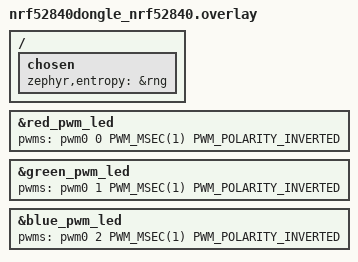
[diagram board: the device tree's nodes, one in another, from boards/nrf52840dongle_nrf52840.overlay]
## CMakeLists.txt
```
#
# Copyright (c) 2018 Nordic Semiconductor
#
# SPDX-License-Identifier: LicenseRef-Nordic-5-Clause
#
cmake_minimum_required(VERSION 3.20.0)

find_package(Zephyr REQUIRED HINTS $ENV{ZEPHYR_BASE})
project(NONE)

FILE(GLOB_RECURSE app_sources src/*.c)
# NORDIC SDK APP START
target_sources(app PRIVATE ${app_sources})
# NORDIC SDK APP END

target_include_directories(app PRIVATE src)

# Force recompile for updated build timestamp
add_custom_target(touch_util_h ALL
    COMMAND ${CMAKE_COMMAND} -E touch ${CMAKE_SOURCE_DIR}/src/build_defines.h
)

target_include_directories(app PRIVATE ${CMAKE_CURRENT_SOURCE_DIR}/../shared)
include(${CMAKE_CURRENT_SOURCE_DIR}/../shared/tdma_hw.cmake)
```

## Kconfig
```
#
# Copyright (c) 2020 Nordic Semiconductor
#
# SPDX-License-Identifier: LicenseRef-Nordic-5-Clause
#

choice
	prompt "Status LED color mapping"
    default LED_TRI_COLOR

config LED_RGB_COLOR
    bool "Use RGB color mapping"
    help
        Use RGB or RG color mapping for LED status if available.

config LED_TRI_COLOR
    bool "Use default color mapping"
    help
        Use the default color mapping for LED status.

endchoice

menu "Status LED default status color"
    depends on LED_RGB_COLOR

config LED_DEFAULT_COLOR_R
    int "Red value"
    range 0 10000
    default 4000
    depends on LED_RGB_COLOR
    help
        Red color for default status.
        Valid range is 0 to 10000.

config LED_DEFAULT_COLOR_G
    int "Green value"
    range 0 10000
    default 6000
    depends on LED_RGB_COLOR
    help
        Green color for default status.
        Valid range is 0 to 10000.

config LED_DEFAULT_COLOR_B
    int "Blue value"
    range 0 10000
    default 0
    depends on LED_RGB_COLOR
    help
        Blue color for default status.
        Valid range is 0 to 10000.

endmenu

config PACKET_LOG
    bool "Link diagnostics and packet log"
    default y
    help
        "diag on" on the console logs radio link diagnostics every interval: frames received and
        lost per tracker (from the frame sequence numbers), repeats, longest silence, RSSI, the
        radio's good/bad CRC counts and the channel's noise floor. Always logged: packets dropped
        by the receiver (unknown id, bad checksum, out of sequence) and trackers gone silent.

config PACKET_LOG_INTERVAL_MS
    int "Log interval (ms)"
    depends on PACKET_LOG
    range 100 60000
    default 1000

config PACKET_LOG_ORIENTATION
    bool "Log each tracker's orientation and packet rate every interval"
    depends on PACKET_LOG
    help
        "Tracker 2 (3CA1B2C4D5E6): orientation X 12.3 Y -4.5 Z 170.2 deg, 98 pkt/s, RSSI ..."
        while "diag" is off.

# "diag on" logs a block of lines every interval; the default 1 KB drops some of them.
config LOG_BUFFER_SIZE
    default 4096 if PACKET_LOG && !SOC_NRF52820

config RECEIVER_BLE
    bool "BLE receiver mode"
    # The Dongle's overlay picks the RNG for entropy (the SoC default, CryptoCell, needs
    # nrf_security); other nRF52840 boards need the same before they can enable it
    default y if BOARD_NRF52840DONGLE
    select BT
    select BT_CENTRAL
    select BT_GATT_CLIENT
    select BT_GATT_DM
    select ESB_DYNAMIC_INTERRUPTS
    select MPSL_DYNAMIC_INTERRUPTS
    help
        Builds a BLE central in beside ESB, for trackers in BLE mode (src/connection/ble.c). The
        receiver_ble setting (console: ble on|off) picks one at boot: the radio runs either ESB
        or BLE, never both; the USB HID output is the same. Changing it reboots the receiver.
        As the tracker (TRACKER_BLE): MPSL keeps its default clock control in both modes and
        stays idle in ESB mode, where ESB takes the radio interrupt over.

if RECEIVER_BLE

config RECEIVER_BLE_MAX_TRACKERS
    int "Trackers connected at once in BLE mode"
    range 1 16
    default 8
    help
        Sets the BLE connections and the connection interval (src/connection/ble.c): each tracker
        gets 1.5 ms of it on 2M (two notification exchanges; 1.9 ms on 1M, RECEIVER_BLE_PHY_1M),
        plus 0.5 ms spare, in 1.25 ms steps: 8 trackers 12.5 ms (up to 160 packets/s each,
        tested), 10 trackers 16.25 ms (~123/s), 12 trackers 18.75 ms (~107/s). The interval is
        fixed for any count connected.

config BT_MAX_CONN
    default RECEIVER_BLE_MAX_TRACKERS

# Each connection 1500 us in the 12.5 ms interval (ble.c, eight trackers): two
# notification exchanges (the controller budgets 27-byte packets both ways, ~0.6 ms each on 2M,
# so 1200 us fitted one); connection event extension gives more while the others leave time
config BT_CTLR_SDC_MAX_CONN_EVENT_LEN_DEFAULT_OVERRIDE
    default y

config BT_CTLR_SDC_MAX_CONN_EVENT_LEN_DEFAULT
    default 1900 if RECEIVER_BLE_PHY_1M
    default 1500

config RECEIVER_BLE_PHY_1M
    bool "BLE on the 1M PHY (range) instead of 2M (rate)"
    help
        The 1M PHY hears about 3 dB weaker signals than 2M (about -95 against -92 dBm), for
        trackers your body blocks; a packet takes twice the air time. The controller's 2M support
        goes, so every link stays on 1M whatever the tracker asks; each tracker gets 1.9 ms of the
        interval (two exchanges budgeted for 27-byte packets both ways, ~0.9 ms each on 1M) and
        the interval follows (ble.c): 8 trackers 16.25 ms (~123 packets/s each), 10 trackers
        20 ms (~100/s).

config BT_CTLR_PHY_2M
    default n if RECEIVER_BLE_PHY_1M

choice BT_AUTO_PHY_CENTRAL
    default BT_AUTO_PHY_CENTRAL_1M if RECEIVER_BLE_PHY_1M
endchoice

choice BT_CTLR_TX_PWR
    default BT_CTLR_TX_PWR_PLUS_8
endchoice

# Each link's PHY in the console's ble status
config BT_USER_PHY_UPDATE
    default y

# HCI Read RSSI, for the RSSI in the HID packets (off by default in the SoftDevice Controller)
config BT_CTLR_CONN_RSSI
    default y

# the BLE host runs parts on the system workqueue (upstream default 1 KB)
config SYSTEM_WORKQUEUE_STACK_SIZE
    default 2048

endif

# LF clock: synthesized from the HF crystal as upstream (no 32 kHz crystal on the Dongle), but
# BLE needs a calibrated RC oscillator under MPSL (500 ppm)
choice CLOCK_CONTROL_NRF_SOURCE
    default CLOCK_CONTROL_NRF_K32SRC_RC if RECEIVER_BLE
    default CLOCK_CONTROL_NRF_K32SRC_SYNTH
endchoice

source "Kconfig.zephyr"
```

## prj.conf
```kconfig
#CONFIG_NCS_SAMPLES_DEFAULTS
CONFIG_ASSERT=y
CONFIG_ASSERT_NO_COND_INFO=y
CONFIG_ASSERT_NO_MSG_INFO=y
CONFIG_RESET_ON_FATAL_ERROR=y

CONFIG_NCS_APPLICATION_BOOT_BANNER_STRING="SlimeVR-Tracker-nRF-Receiver"
#CONFIG_NCS_BOOT_BANNER=n
CONFIG_BOOT_BANNER=n

CONFIG_ESB=y
CONFIG_NEWLIB_LIBC=y
CONFIG_CBPRINTF_FP_SUPPORT=y

CONFIG_FPU=y

CONFIG_USB_DEVICE_STACK=y
CONFIG_USB_DEVICE_HID=y
CONFIG_USB_DEVICE_VID=0x1209
CONFIG_USB_DEVICE_PID=0x7690
CONFIG_USB_HID_BOOT_PROTOCOL=y
CONFIG_USB_DEVICE_INITIALIZE_AT_BOOT=n
CONFIG_USB_CDC_ACM=y
CONFIG_UART_INTERRUPT_DRIVEN=y
#CONFIG_USB_WORKQUEUE_STACK_SIZE=512

CONFIG_SERIAL=y
CONFIG_CONSOLE=y
CONFIG_UART_CONSOLE=y
CONFIG_UART_LINE_CTRL=y

CONFIG_USE_SEGGER_RTT=y
CONFIG_LOG=y
#CONFIG_PRINTK=y
CONFIG_LOG_MODE_DEFERRED=y
CONFIG_LOG_SPEED=y
CONFIG_LOG_BACKEND_RTT=y
CONFIG_USB_DRIVER_LOG_LEVEL_WRN=y
CONFIG_USB_DEVICE_LOG_LEVEL_WRN=y
CONFIG_USB_CDC_ACM_LOG_LEVEL_OFF=y
CONFIG_LOG_PROCESS_THREAD_SLEEP_MS=100
CONFIG_LOG_PROCESS_THREAD_STACK_SIZE=1024
CONFIG_LOG_PROCESS_THREAD_STARTUP_DELAY_MS=0

CONFIG_LOG_BACKEND_UART=y
CONFIG_LOG_MODE_DEFERRED=y

CONFIG_CONSOLE_SUBSYS=y
CONFIG_CONSOLE_GETLINE=y

CONFIG_NVS_LOG_LEVEL_WRN=y
CONFIG_USB_HID_LOG_LEVEL_WRN=y

CONFIG_USB_DEVICE_SOF=y
CONFIG_USB_HID_REPORTS=256

CONFIG_USB_HID_POLL_INTERVAL_MS=1
CONFIG_HID_INTERRUPT_EP_MPS=64
CONFIG_ENABLE_HID_INT_OUT_EP=y

CONFIG_GPIO=y
CONFIG_PWM=y

CONFIG_NVS=y

CONFIG_FLASH=y
CONFIG_FLASH_PAGE_LAYOUT=y
CONFIG_FLASH_MAP=y

CONFIG_SETTINGS=y
CONFIG_SETTINGS_NVS=y
CONFIG_SETTINGS_RUNTIME=y
CONFIG_SETTINGS_NONE=y

CONFIG_MPU_ALLOW_FLASH_WRITE=y

CONFIG_NVS_LOOKUP_CACHE=y

CONFIG_ESB_TX_FIFO_SIZE=1
# deprecated?
#CONFIG_NRFX_TIMER1=y

#speed up boot? (use internal rc oscillator)
#CONFIG_CLOCK_CONTROL_NRF_K32SRC_RC=y
#speed up boot? (synthesize lf clock)
# SYNTH, unless the BLE mode is built in (Kconfig, RECEIVER_BLE: calibrated RC)
#CONFIG_CLOCK_CONTROL_NRF_K32SRC_SYNTH=y

# dont need it
CONFIG_CRYPTO=n

CONFIG_THREAD_NAME=y
#CONFIG_SYSTEM_WORKQUEUE_STACK_SIZE=256
CONFIG_MAIN_STACK_SIZE=512

#CONFIG_HEAP_MEM_POOL_SIZE=2048
CONFIG_ISR_STACK_SIZE=1024
```

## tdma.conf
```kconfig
# Experimental; requires TDMA firmware on every tracker for collision isolation.
CONFIG_RADIO_TDMA=y
CONFIG_STACK_USAGE=y
```

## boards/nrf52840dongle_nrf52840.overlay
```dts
&red_pwm_led {
	pwms = <&pwm0 0 PWM_MSEC(1) PWM_POLARITY_INVERTED>;
};
&green_pwm_led {
	pwms = <&pwm0 1 PWM_MSEC(1) PWM_POLARITY_INVERTED>;
};
&blue_pwm_led {
	pwms = <&pwm0 2 PWM_MSEC(1) PWM_POLARITY_INVERTED>;
};

/* BLE mode (CONFIG_RECEIVER_BLE): random numbers from the RNG peripheral. The SoC default is
 * CryptoCell, whose driver needs nrf_security. */
/ {
	chosen {
		zephyr,entropy = &rng;
	};
};
```

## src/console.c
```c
/*
	SlimeVR Code is placed under the MIT license
	Copyright (c) 2025 SlimeVR Contributors

	Permission is hereby granted, free of charge, to any person obtaining a copy
	of this software and associated documentation files (the "Software"), to deal
	in the Software without restriction, including without limitation the rights
	to use, copy, modify, merge, publish, distribute, sublicense, and/or sell
	copies of the Software, and to permit persons to whom the Software is
	furnished to do so, subject to the following conditions:

	The above copyright notice and this permission notice shall be included in
	all copies or substantial portions of the Software.

	THE SOFTWARE IS PROVIDED "AS IS", WITHOUT WARRANTY OF ANY KIND, EXPRESS OR
	IMPLIED, INCLUDING BUT NOT LIMITED TO THE WARRANTIES OF MERCHANTABILITY,
	FITNESS FOR A PARTICULAR PURPOSE AND NONINFRINGEMENT. IN NO EVENT SHALL THE
	AUTHORS OR COPYRIGHT HOLDERS BE LIABLE FOR ANY CLAIM, DAMAGES OR OTHER
	LIABILITY, WHETHER IN AN ACTION OF CONTRACT, TORT OR OTHERWISE, ARISING FROM,
	OUT OF OR IN CONNECTION WITH THE SOFTWARE OR THE USE OR OTHER DEALINGS IN
	THE SOFTWARE.
*/
#include "connection/ble.h"
#include "globals.h"
#include "system/system.h"
#include "build_defines.h"
#include "parse_args.h"
#include "packet_log.h"
#include "ota.h"
#include "remote_config.h"

#define USB DT_NODELABEL(usbd)
#if DT_NODE_HAS_STATUS(USB, okay)

#include <zephyr/drivers/gpio.h>
#include <zephyr/console/console.h>
#include <stdlib.h>
#include <zephyr/sys/reboot.h>
#include <zephyr/logging/log_ctrl.h>
#include "connection/esb.h"

#include <ctype.h>

#define DFU_DBL_RESET_MEM 0x20007F7C
#define DFU_DBL_RESET_APP 0x4ee5677e

uint32_t* dbl_reset_mem = ((uint32_t*) DFU_DBL_RESET_MEM);

LOG_MODULE_REGISTER(console, LOG_LEVEL_INF);

static void console_thread(void);
K_THREAD_DEFINE(console_thread_id, 1024, console_thread, NULL, NULL, NULL, 6, 0, 0);

#define DFU_EXISTS CONFIG_BUILD_OUTPUT_UF2 || CONFIG_BOARD_HAS_NRF5_BOOTLOADER
#define ADAFRUIT_BOOTLOADER CONFIG_BUILD_OUTPUT_UF2
#define NRF5_BOOTLOADER CONFIG_BOARD_HAS_NRF5_BOOTLOADER

#if NRF5_BOOTLOADER
static const struct device *gpio_dev = DEVICE_DT_GET(DT_NODELABEL(gpio0));
#endif

static const char *meows[] = {
	"Mew",
	"Meww",
	"Meow",
	"Meow meow",
	"Mrrrp",
	"Mrrf",
	"Mreow",
	"Mrrrow",
	"Mrrr",
	"Purr",
	"mew",
	"meww",
	"meow",
	"meow meow",
	"mrrrp",
	"mrrf",
	"mreow",
	"mrrrow",
	"mrrr",
	"purr",
};

static const char *meow_punctuations[] = {
	".",
	"?",
	"!",
	"-",
	"~",
	""
};

static const char *meow_suffixes[] = {
	" :3",
	" :3c",
	" ;3",
	" ;3c",
	" x3",
	" x3c",
	" X3",
	" X3c",
	" >:3",
	" >:3c",
	" >;3",
	" >;3c",
	""
};

static void skip_dfu(void)
{
#if DFU_EXISTS // Using Adafruit bootloader
	(*dbl_reset_mem) = DFU_DBL_RESET_APP; // Skip DFU
	ram_range_retain(dbl_reset_mem, sizeof(dbl_reset_mem), true);
#endif
}

static void print_info(void)
{
	printk(CONFIG_USB_DEVICE_MANUFACTURER " " CONFIG_USB_DEVICE_PRODUCT "\n");
	printk(FW_STRING);

	printk("\nBoard: " CONFIG_BOARD "\n");
	printk("SOC: " CONFIG_SOC "\n");
	printk("Target: " CONFIG_BOARD_TARGET "\n");

	printk("\nDevice address: %012llX\n", *(uint64_t *)NRF_FICR->DEVICEADDR & 0xFFFFFFFFFFFF);
}

static void print_uptime(void)
{
	int64_t uptime = k_ticks_to_us_floor64(k_uptime_ticks());

	uint32_t days = uptime / 86400000000;
	uptime %= 86400000000;
	uint8_t hours = uptime / 3600000000;
	uptime %= 3600000000;
	uint8_t minutes = uptime / 60000000;
	uptime %= 60000000;
	uint8_t seconds = uptime / 1000000;
	uptime %= 1000000;
	uint16_t milliseconds = uptime / 1000;
	uint16_t microseconds = uptime %= 1000;

	printk("Uptime: %u.%02u:%02u:%02u.%03u,%03u\n", days, hours, minutes, seconds, milliseconds, microseconds);
}

static void print_meow(void)
{
	int64_t ticks = k_uptime_ticks();

	ticks %= ARRAY_SIZE(meows) * ARRAY_SIZE(meow_punctuations) * ARRAY_SIZE(meow_suffixes); // silly number generator
	uint8_t meow = ticks / (ARRAY_SIZE(meow_punctuations) * ARRAY_SIZE(meow_suffixes));
	ticks %= (ARRAY_SIZE(meow_punctuations) * ARRAY_SIZE(meow_suffixes));
	uint8_t punctuation = ticks / ARRAY_SIZE(meow_suffixes);
	uint8_t suffix = ticks % ARRAY_SIZE(meow_suffixes);

	printk("%s%s%s\n", meows[meow], meow_punctuations[punctuation], meow_suffixes[suffix]);
}

static void print_list(void)
{
	printk("Stored devices:\n");
	for (uint8_t i = 0; i < stored_trackers; i++)
		printk("%012llX%s\n", stored_tracker_addr[i], stored_tracker_addr[i] ? "" : " (free, unpaired)");
}

static inline void strtolower(char *str) {
	for(int i = 0; str[i]; i++) {
		str[i] = tolower(str[i]);
	}
}

static void print_help(void)
{
	printk("\nhelp                         Display this help text\n");

	printk("\ninfo                         Get device information\n");
	printk("uptime                       Get device uptime\n");
	printk("list                         Get paired devices\n");
	printk("reboot                       Soft reset the device\n");
	printk("\nadd <address>                Manually add a device\n");
	printk("remove                       Remove last device\n");
	printk("unpair <id>                  Remove that device; the others keep their ids\n");
	printk("pair                         Enter pairing mode\n");
	printk("exit                         Exit pairing mode\n");
	printk("clear                        Clear stored devices\n");
#if CONFIG_PACKET_LOG
	printk("\ndiag [on|off]                Log radio link diagnostics every second (off at boot)\n");
#endif
	printk("ota [status|stop]            Tracker firmware updates over the radio (tools/ota.py)\n");
	printk("cfg <id> get|set|reset ...   Tracker settings over the radio (tools/remote_config.py)\n");
#if CONFIG_RECEIVER_BLE
	printk("ble [on|off]                 BLE status, or switch to BLE / ESB (reboots)\n");
#endif
#if DFU_EXISTS
	printk("\ndfu                          Enter DFU bootloader\n");
#endif
	printk("\nmeow                         Meow!\n");
}

static void console_thread(void)
{
	console_getline_init();
	while (log_data_pending())
		k_usleep(1);
	k_msleep(100);
	printk("*** " CONFIG_USB_DEVICE_MANUFACTURER " " CONFIG_USB_DEVICE_PRODUCT " ***\n");
	printk(FW_STRING);
	print_help();

	const char command_help[] = "help";

	const char command_info[] = "info";
	const char command_uptime[] = "uptime";
	const char command_list[] = "list";
	const char command_reboot[] = "reboot";
	const char command_add[] = "add";
	const char command_remove[] = "remove";
	const char command_pair[] = "pair";
	const char command_exit[] = "exit";
	const char command_clear[] = "clear";
#if DFU_EXISTS
	const char command_dfu[] = "dfu";
#endif
	const char command_meow[] = "meow";
	const char command_diag[] = "diag";

	while (1) {
		char *line = console_getline();

		char* argv[8] = {NULL}; // command and up to 6 args (the parser rejects a full array; ota begin has 4)
		size_t argc = parse_args(line, argv, ARRAY_SIZE(argv));
		if(argc == 0)
			continue;
		if(argc > 0)
			strtolower(argv[0]); // lower case the command
		if(argc > 1)
			strtolower(argv[1]); // lower case the first argument
		// only care that the first words are matchable

		if (strcmp(argv[0], command_help) == 0)
		{
			print_help();
		}
		else if (strcmp(argv[0], command_info) == 0)
		{
			print_info();
		}
		else if (strcmp(line, command_uptime) == 0)
		{
			print_uptime();
		}
		else if (strcmp(line, command_add) == 0)
		{
			if (argc != 2)
			{
				printk("Invalid number of arguments\n");
				continue;
			}
			uint64_t addr = parse_u64(argv[1], 16);
			uint8_t buf[13];
			snprintk(buf, 13, "%012llx", addr);
			if (addr != 0 && strcmp(buf, argv[1]) == 0)
				esb_add_pair(addr, true);
			else
				printk("Invalid address\n");
		}
		else if (strcmp(line, command_remove) == 0)
		{
			esb_pop_pair();
			ble_disconnect_all(); // ids anew as they reconnect
		}
		else if (strcmp(line, command_list) == 0)
		{
			print_list();
		}
		else if (strcmp(line, command_reboot) == 0)
		{
			skip_dfu();
			sys_reboot(SYS_REBOOT_COLD);
		}
		else if (strcmp(line, command_pair) == 0)
		{
			if (ble_mode())
				ble_set_pairing(true);
			else
				esb_reset_pair();
			printk("Pairing on%s\n", ble_mode() ? " (BLE: new trackers in BLE mode are added when they connect)" : "");
		}
		else if (strcmp(line, command_exit) == 0)
		{
			if (ble_mode())
				ble_set_pairing(false);
			else
				esb_finish_pair();
			printk("Pairing off\n");
		}
		else if (strcmp(argv[0], "unpair") == 0)
		{
			char *end = NULL;
			unsigned long id = argc == 2 ? strtoul(argv[1], &end, 10) : 0;
			if (argc != 2 || !end || *end || id > 255)
				printk("Usage: unpair <id>\n");
			else if (esb_unpair(id))
				printk("Unpair: no device on id %lu\n", id);
			else
			{
				ble_disconnect_id(id);
				printk("Unpaired id %lu\n", id);
			}
		}
		else if (strcmp(line, command_clear) == 0)
		{
			esb_clear();
			ble_disconnect_all(); // ids anew as they reconnect
		}
#if CONFIG_RECEIVER_BLE
		else if (strcmp(argv[0], "ble") == 0)
		{
			if (argc == 2 && (strcmp(argv[1], "on") == 0 || strcmp(argv[1], "off") == 0))
				ble_set_mode(strcmp(argv[1], "on") == 0);
			else if (argc == 1)
				ble_print_status();
			else
				printk("Usage: ble [on|off]\n");
		}
#endif
#if DFU_EXISTS
		else if (strcmp(line, command_dfu) == 0)
		{
#if ADAFRUIT_BOOTLOADER
			NRF_POWER->GPREGRET = 0x57;
			sys_reboot(SYS_REBOOT_COLD);
#endif
#if NRF5_BOOTLOADER
			gpio_pin_configure(gpio_dev, 19, GPIO_OUTPUT | GPIO_OUTPUT_INIT_LOW);
#endif
		}
#endif
		else if (strcmp(line, command_meow) == 0)
		{
			print_meow();
		}
		else if (strcmp(argv[0], "ota") == 0)
		{
			ota_console(argc, argv);
		}
		else if (strcmp(argv[0], "cfg") == 0)
		{
			remote_config_console(argc, argv);
		}
		else if (strcmp(argv[0], command_diag) == 0)
		{
			if (!IS_ENABLED(CONFIG_PACKET_LOG))
				printk("This build has no link diagnostics\n");
			else
			{
				if (argc > 1 && (strcmp(argv[1], "on") == 0 || strcmp(argv[1], "off") == 0))
					packet_log_set_diag(strcmp(argv[1], "on") == 0);
				else if (argc > 1)
					printk("Usage: diag [on|off]\n");
				printk("Link diagnostics %s\n", packet_log_diag() ? "on" : "off");
				if (packet_log_diag())
					printk("Every second:\n"
					       "  diag noise: background RSSI while listening; the median is the noise floor (clean: about -95)\n"
					       "  diag radio: frames the radio received with a good / bad CRC, all trackers\n"
					       "  diag id N: rx frames, lost = sequence numbers that never arrived,\n"
					       "    dup = repeats (tracker missed the ACK), late = older after newer,\n"
					       "    max gap = longest silence, RSSI average (worst),\n"
					       "    |...| = 50 ms slots: # frames, x frames after lost ones, . nothing\n"
					       "  diag gap / outage: a silence that lost frames, or over 1 s\n");
			}
		}
		else
		{
			printk("Unknown command\n");
		}
	}
}

#endif
```

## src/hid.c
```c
/*
	SlimeVR Code is placed under the MIT license
	Copyright (c) 2025 SlimeVR Contributors

	Permission is hereby granted, free of charge, to any person obtaining a copy
	of this software and associated documentation files (the "Software"), to deal
	in the Software without restriction, including without limitation the rights
	to use, copy, modify, merge, publish, distribute, sublicense, and/or sell
	copies of the Software, and to permit persons to whom the Software is
	furnished to do so, subject to the following conditions:

	The above copyright notice and this permission notice shall be included in
	all copies or substantial portions of the Software.

	THE SOFTWARE IS PROVIDED "AS IS", WITHOUT WARRANTY OF ANY KIND, EXPRESS OR
	IMPLIED, INCLUDING BUT NOT LIMITED TO THE WARRANTIES OF MERCHANTABILITY,
	FITNESS FOR A PARTICULAR PURPOSE AND NONINFRINGEMENT. IN NO EVENT SHALL THE
	AUTHORS OR COPYRIGHT HOLDERS BE LIABLE FOR ANY CLAIM, DAMAGES OR OTHER
	LIABILITY, WHETHER IN AN ACTION OF CONTRACT, TORT OR OTHERWISE, ARISING FROM,
	OUT OF OR IN CONNECTION WITH THE SOFTWARE OR THE USE OR OTHER DEALINGS IN
	THE SOFTWARE.
*/
#include "globals.h"
#include "packet_log.h"
#include "ota.h"

#include <zephyr/kernel.h>
#include <zephyr/usb/usb_device.h>
#include <zephyr/usb/class/usb_hid.h>

static struct k_work report_send;
static struct k_work report_read;

static struct tracker_report {
	uint8_t data[16];
} __packed report = {
	.data = {0}
};;

struct tracker_report reports[MAX_TRACKERS];
atomic_t report_write_index = 0;
atomic_t report_read_index = 0;
// read_index == write_index -> empty fifo
// (write_index + 1) % MAX_TRACKERS == read_index -> full fifo

static bool configured;
static const struct device *hdev;
static ATOMIC_DEFINE(hid_ep_in_busy, 1);
static ATOMIC_DEFINE(hid_ep_out_busy, 1);

#define HID_EP_BUSY_FLAG	0
#define REPORT_PERIOD		K_MSEC(1) // streaming reports // TODO: could it be shorter/reduce latency?
#define POLL_PERIOD		K_MSEC(1) // streaming reports // TODO: could it be shorter/reduce latency?
#define HID_EP_REPORT_COUNT 4

struct tracker_report ep_report_buffer[HID_EP_REPORT_COUNT];
uint8_t ep_read_buffer[256]; // TODO: no struct // TODO: is possible to read >64 bytes, e.g. a delayed read?

LOG_MODULE_REGISTER(hid_event, LOG_LEVEL_INF);

static void report_event_handler(struct k_timer *dummy);
static K_TIMER_DEFINE(event_timer, report_event_handler, NULL);

static void report_read_handler(struct k_timer *dummy);
static K_TIMER_DEFINE(read_timer, report_read_handler, NULL);

static const uint8_t hid_report_desc[] = {
	HID_USAGE_PAGE(HID_USAGE_GEN_DESKTOP),
	HID_USAGE(HID_USAGE_GEN_DESKTOP_UNDEFINED),
	HID_COLLECTION(HID_COLLECTION_APPLICATION),
		HID_USAGE(HID_USAGE_GEN_DESKTOP_UNDEFINED),
		HID_REPORT_SIZE(8),
		HID_REPORT_COUNT(64),
		HID_INPUT(0x02),
		HID_USAGE(HID_USAGE_GEN_DESKTOP_UNDEFINED),
		HID_REPORT_SIZE(8),
		HID_REPORT_COUNT(64),
		HID_OUTPUT(0x02),
	HID_END_COLLECTION,
};

uint16_t sent_device_addr = 0;
bool usb_enabled = false;
int64_t last_registration_sent = 0;

//|type    |description
//|TX   255|receiver packet 0, associate id and tracker address
//|TX   254|device list hash, round trip ping
//|TX   253|receiver status (TODO: send number of pairing requests found?)
//|TX   252|device pairing request, id is the id of the pairing request in case of multiple, not final tracker id (TODO: these can timeout if not sent often? can server automatically accept if the address was known?)
//|RX   255|round trip response
//|RX   254|command (TODO: include parameters?)

//|b0      |b1      |b2      |b3      |b4      |b5      |b6      |b7      |b8      |b9      |b10     |b11     |b12     |b13     |b14     |b15     |
//|type    |data                                                                                                                                  |
//|TX   255|id      |device_addr                                          |resv-------------------------------------------------------------------|
//|TX   254|stored  |crc                                |latency          |resv-------------------------------------------------------------------|
//|TX   253|status  |resv-------------------------------------------------|resv-------------------------------------------------------------------|
//|TX   252|id      |device_addr                                          |resv-------------------------------------------------------------------|
//|RX   255|resv----------------------------------------------------------|resv-------------------------------------------------------------------|
//|RX   254|command |resv-------------------------------------------------|resv-------------------------------------------------------------------|

// TODO: implement this

static void packet_device_addr(uint8_t *report, uint16_t id) // associate id and tracker address
{
	report[0] = 255; // receiver packet 0
	report[1] = id;
	memcpy(&report[2], &stored_tracker_addr[id], 6);
	memset(&report[8], 0, 8); // last 8 bytes unused for now
}

static uint32_t dropped_reports = 0;
static uint16_t max_dropped_reports = 0;

// The next paired id after `id`, round robin, skipping ids freed by unpair (address 0); -1: none
static int next_paired(int id)
{
	for (int k = 0; k < stored_trackers; k++)
	{
		id = (id + 1) % stored_trackers;
		if (stored_tracker_addr[id])
			return id;
	}
	return -1;
}

static void send_report(struct k_work *work)
{
	if (!usb_enabled) return;
	if (next_paired(0) < 0) return; // no paired tracker (an empty slot would read as a tracker packet)

	// Get current FIFO status atomically
	size_t write_idx = (size_t)atomic_get(&report_write_index);
	size_t read_idx = (size_t)atomic_get(&report_read_index);

	if (write_idx == read_idx && k_uptime_get() - 100 < last_registration_sent) {
		return; // send registrations only every 100ms
	}

	int ret, wrote;

	last_registration_sent = k_uptime_get();

	if (!atomic_test_and_set_bit(hid_ep_in_busy, HID_EP_BUSY_FLAG)) {
		// Calculate how many reports we have available
		int available_reports = write_idx - read_idx;
		if (available_reports < 0) available_reports += MAX_TRACKERS;
		size_t reports_to_send = (size_t)((available_reports > HID_EP_REPORT_COUNT) ? HID_EP_REPORT_COUNT : available_reports);

		int epind;
		// Copy existing data to buffer
		for (epind = 0; epind < reports_to_send; epind++) {
			ep_report_buffer[epind] = reports[read_idx];
			read_idx++;
			if (read_idx == MAX_TRACKERS) read_idx = 0;
			atomic_set(&report_read_index, read_idx);
		}

		// Pad remaining report slots with device addr
		for (; epind < HID_EP_REPORT_COUNT; epind++) {
			int id = next_paired(sent_device_addr);
			if (id >= 0) {
				sent_device_addr = id;
				packet_device_addr(ep_report_buffer[epind].data, sent_device_addr);
			}
		}

		ret = hid_int_ep_write(hdev, (uint8_t *)ep_report_buffer, sizeof(report) * HID_EP_REPORT_COUNT, &wrote);

		if (ret != 0) {
			/*
			 * Do nothing and wait until host has reset the device
			 * and hid_ep_in_busy is cleared.
			 */
			LOG_ERR("Failed to submit report");
		} else {
			//LOG_DBG("Report submitted");
		}
	} else { // busy with what
		//LOG_DBG("HID IN endpoint busy");
	}
}

#define DROPPED_REPORT_LOG_INTERVAL 5000

static void hid_dropped_reports_logging(void)
{
	while (1) {
		if (dropped_reports) LOG_INF("Dropped reports: %u (max: %u)", dropped_reports, max_dropped_reports);
		dropped_reports = 0;
		max_dropped_reports = 0;
		k_msleep(DROPPED_REPORT_LOG_INTERVAL);
	}
}

K_THREAD_DEFINE(hid_dropped_reports_logging_thread, 256, hid_dropped_reports_logging, NULL, NULL, NULL, 6, 0, 0);

static void read_report(struct k_work *work)
{
	if (!usb_enabled) return;

	int ret, read;

	if (!atomic_test_and_set_bit(hid_ep_out_busy, HID_EP_BUSY_FLAG)) {
		ret = hid_int_ep_read(hdev, (uint8_t *)ep_read_buffer, sizeof(ep_read_buffer), &read);

		if (ret != 0) {
			LOG_ERR("hid_int_ep_read: %d", ret);
		} else if (read > 0 && ep_read_buffer[0] == OTA_HID_DATA) {
			ota_hid_data(ep_read_buffer, read); // a tracker firmware update streamed by the PC
		} else {
			LOG_INF("hid_int_ep_read: %d", read);
			// do something here
			LOG_INF("%016llX%016llX%016llX%016llX%016llX%016llX%016llX%016llX",
				*(uint64_t *)(ep_read_buffer + 56),
				*(uint64_t *)(ep_read_buffer + 48),
				*(uint64_t *)(ep_read_buffer + 40),
				*(uint64_t *)(ep_read_buffer + 32),
				*(uint64_t *)(ep_read_buffer + 24),
				*(uint64_t *)(ep_read_buffer + 16),
				*(uint64_t *)(ep_read_buffer + 8),
				*(uint64_t *)ep_read_buffer
			);
		}
	} else { // busy with what
		//LOG_DBG("HID OUT endpoint busy");
	}
}

static void int_in_ready_cb(const struct device *dev)
{
	ARG_UNUSED(dev);
	if (!atomic_test_and_clear_bit(hid_ep_in_busy, HID_EP_BUSY_FLAG)) {
		LOG_WRN("IN endpoint callback without preceding buffer write");
	}
	// TODO: can probably immediately write report from here
}

static void int_out_ready_cb(const struct device *dev)
{
	ARG_UNUSED(dev);
	if (!atomic_test_and_clear_bit(hid_ep_out_busy, HID_EP_BUSY_FLAG)) {
		LOG_WRN("OUT endpoint callback without preceding buffer write");
	}
	// TODO: can probably immediately read report from here
}

/*
 * On Idle callback is available here as an example even if actual use is
 * very limited. In contrast to report_event_handler(),
 * report value is not incremented here.
 */
static void on_idle_cb(const struct device *dev, uint16_t report_id)
{
	LOG_DBG("On idle callback");
	k_work_submit(&report_send);
}

static void report_event_handler(struct k_timer *dummy)
{
	if (usb_enabled)
		k_work_submit(&report_send);
}

static void report_read_handler(struct k_timer *dummy)
{
	if (usb_enabled)
		k_work_submit(&report_read);
}

static void protocol_cb(const struct device *dev, uint8_t protocol)
{
	LOG_INF("New protocol: %s", protocol == HID_PROTOCOL_BOOT ?
		"boot" : "report");
}

static const struct hid_ops ops = {
	.int_in_ready = int_in_ready_cb,
	.int_out_ready = int_out_ready_cb,
	.on_idle = on_idle_cb,
	.protocol_change = protocol_cb,
};

static void status_cb(enum usb_dc_status_code status, const uint8_t *param)
{
	switch (status) {
	case USB_DC_RESET:
		configured = false;
		break;
	case USB_DC_CONFIGURED:
		int configurationIndex = *param;
		if(configurationIndex == 0) {
			// from usb_device.c: A configuration index of 0 unconfigures the device.
			configured = false;
		} else {
			if (!configured) {
				int_in_ready_cb(hdev);
				configured = true;
			}
		}
		break;
	case USB_DC_SOF:
		break;
	default:
		LOG_DBG("status %u unhandled", status);
		break;
	}
}

static int composite_pre_init()
{
	hdev = device_get_binding("HID_0");
	if (hdev == NULL) {
		LOG_ERR("Cannot get USB HID Device");
		return -ENODEV;
	}

	LOG_INF("HID Device: dev %p", hdev);

	usb_hid_register_device(hdev, hid_report_desc, sizeof(hid_report_desc),
				&ops);

	atomic_set_bit(hid_ep_in_busy, HID_EP_BUSY_FLAG);
	k_timer_start(&event_timer, REPORT_PERIOD, REPORT_PERIOD);

	atomic_set_bit(hid_ep_out_busy, HID_EP_BUSY_FLAG);
	k_timer_start(&read_timer, POLL_PERIOD, POLL_PERIOD);

	if (usb_hid_set_proto_code(hdev, HID_BOOT_IFACE_CODE_NONE)) {
		LOG_WRN("Failed to set Protocol Code");
	}

	return usb_hid_init(hdev);
}

SYS_INIT(composite_pre_init, APPLICATION, CONFIG_KERNEL_INIT_PRIORITY_DEVICE);

void usb_init_thread(void)
{
	usb_enable(status_cb);
	k_work_init(&report_send, send_report);
	k_work_init(&report_read, read_report);
	usb_enabled = true;
}

K_THREAD_DEFINE(usb_init_thread_id, 256, usb_init_thread, NULL, NULL, NULL, 6, 0, 0);

//|type    |description
//|RX     0|device info ("info")
//|RX     1|full precision quat and accel
//|RX     2|reduced precision quat and accel with battery, temp, and rssi ("info")
//|RX     3|status ("status")
//|RX     4|full precision quat and magnetometer
//|RX     5|runtime ("status2")
//|RX     6|reduced precision quat and accel with button and sleep time ("info2")
//|RX     7|button and sleep time ("info2")

//|b0      |b1      |b2      |b3      |b4      |b5      |b6      |b7      |b8      |b9      |b10     |b11     |b12     |b13     |b14     |b15     |
//|type    |id      |packet data                                                                                                                  |
//|RX     0|id      |batt    |batt_v  |temp    |brd_id  |mcu_id  |resv----|imu_id  |mag_id  |fw_date          |major   |minor   |patch   |rssi    |
//|RX     1|id      |q0               |q1               |q2               |q3               |a0               |a1               |a2               |
//|RX     2|id      |batt    |batt_v  |temp    |q_buf                              |a0               |a1               |a2               |rssi    |
//|RX     3|id      |svr_stat|status  |resv----------------------------------------------------------------------------------------------|rssi    |
//|RX     4|id      |q0               |q1               |q2               |q3               |m0               |m1               |m2               |
//|RX     5|id      |runtime                                                                |resv----------------------------------------|rssi    |
//|RX     6|id      |button  |sleeptime        |resv-------------------------------------------------------------------------------------|rssi    |
//|RX     7|id      |button  |sleeptime        |q_buf                              |a0               |a1               |a2               |rssi    |

// runtime is in microseconds (overkill), sleeptime is in milliseconds (overkill but less)

void hid_write_packet_n(uint8_t *data, uint8_t rssi)
{
	memcpy(&report.data, data, sizeof(report)); // all data can be passed through
	if (data[0] != 1 && data[0] != 4) // packet 1 and 4 are full precision quat and accel/mag, no room for rssi
		report.data[15] = rssi;
	packet_log_put(report.data, rssi);
	// Get current FIFO status atomically
	size_t write_idx = (size_t)atomic_get(&report_write_index);
	size_t read_idx = (size_t)atomic_get(&report_read_index);

	// Try to replace existing entry for the same tracker first
	if (write_idx != read_idx) {
		// Start from read point + 1 to avoid hitting the entry being used
		size_t check_index = read_idx + 1;
		if (check_index == MAX_TRACKERS) check_index = 0;

		while (check_index != write_idx) {
			if (reports[check_index].data[1] == data[1]) {
				// Replace existing entry
				reports[check_index] = report;
				return;
			}
			check_index = check_index + 1;
			if (check_index == MAX_TRACKERS) check_index = 0;
		}
	}
	if (write_idx + 1 == read_idx || (write_idx == MAX_TRACKERS-1 && read_idx == 0)) { // overflow
		dropped_reports ++;
		return;
	}
	// Write new packet into FIFO
	reports[write_idx] = report;

	// Update write index atomically
	write_idx ++;
	if (write_idx == MAX_TRACKERS) write_idx = 0;
	atomic_set(&report_write_index, write_idx);
}
```

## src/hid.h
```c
/*
	SlimeVR Code is placed under the MIT license
	Copyright (c) 2025 SlimeVR Contributors

	Permission is hereby granted, free of charge, to any person obtaining a copy
	of this software and associated documentation files (the "Software"), to deal
	in the Software without restriction, including without limitation the rights
	to use, copy, modify, merge, publish, distribute, sublicense, and/or sell
	copies of the Software, and to permit persons to whom the Software is
	furnished to do so, subject to the following conditions:

	The above copyright notice and this permission notice shall be included in
	all copies or substantial portions of the Software.

	THE SOFTWARE IS PROVIDED "AS IS", WITHOUT WARRANTY OF ANY KIND, EXPRESS OR
	IMPLIED, INCLUDING BUT NOT LIMITED TO THE WARRANTIES OF MERCHANTABILITY,
	FITNESS FOR A PARTICULAR PURPOSE AND NONINFRINGEMENT. IN NO EVENT SHALL THE
	AUTHORS OR COPYRIGHT HOLDERS BE LIABLE FOR ANY CLAIM, DAMAGES OR OTHER
	LIABILITY, WHETHER IN AN ACTION OF CONTRACT, TORT OR OTHERWISE, ARISING FROM,
	OUT OF OR IN CONNECTION WITH THE SOFTWARE OR THE USE OR OTHER DEALINGS IN
	THE SOFTWARE.
*/
#ifndef SLIMENRF_HID
#define SLIMENRF_HID

#include <stdint.h>

void hid_write_packet_n(uint8_t *data, uint8_t rssi);

#endif
```

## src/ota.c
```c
/*
	SlimeVR Code is placed under the MIT license
	Copyright (c) 2026 SlimeVR Contributors

	Permission is hereby granted, free of charge, to any person obtaining a copy
	of this software and associated documentation files (the "Software"), to deal
	in the Software without restriction, including without limitation the rights
	to use, copy, modify, merge, publish, distribute, sublicense, and/or sell
	copies of the Software, and to permit persons to whom the Software is
	furnished to do so, subject to the following conditions:

	The above copyright notice and this permission notice shall be included in
	all copies or substantial portions of the Software.

	THE SOFTWARE IS PROVIDED "AS IS", WITHOUT WARRANTY OF ANY KIND, EXPRESS OR
	IMPLIED, INCLUDING BUT NOT LIMITED TO THE WARRANTIES OF MERCHANTABILITY,
	FITNESS FOR A PARTICULAR PURPOSE AND NONINFRINGEMENT. IN NO EVENT SHALL THE
	AUTHORS OR COPYRIGHT HOLDERS BE LIABLE FOR ANY CLAIM, DAMAGES OR OTHER
	LIABILITY, WHETHER IN AN ACTION OF CONTRACT, TORT OR OTHERWISE, ARISING FROM,
	OUT OF OR IN CONNECTION WITH THE SOFTWARE OR THE USE OR OTHER DEALINGS IN
	THE SOFTWARE.
*/
#include "ota.h"
#include "ota_proto.h"
#include "remote_config.h"

#include <stdlib.h>
#include <string.h>
#include <zephyr/kernel.h>
#include <zephyr/logging/log.h>

LOG_MODULE_REGISTER(ota, LOG_LEVEL_INF);

// The PC streams the image into this window (HID OUT reports, ota_hid_data) while the tracker
// fetches it. The tracker only ever asks for the offset after the last chunk it has, so the window
// needs to hold only what lies between that offset and what the PC has sent; the PC reads where
// the tracker is from the status and never runs more than WINDOW bytes ahead of it.
#define WINDOW 16384
#define STALL_TIMEOUT_MS 10000

static uint8_t window[WINDOW];

enum { OTA_IDLE, OTA_OFFERING, OTA_SENDING };
static const char *const state_names[] = {"idle", "offering", "sending"};

static atomic_t state = ATOMIC_INIT(OTA_IDLE);
static uint32_t img_size, img_crc, img_board;
static uint8_t target;
static uint8_t session; // 1 - OTA_SESSIONS, new with every offer
static volatile uint32_t received; // bytes the PC has sent
static volatile uint32_t asked;    // offset the tracker asked for last: everything below it is done
static uint32_t next_log;
static int64_t start_time;

// How the last update ended, logged and kept for the status: a log line can be lost on the
// console (cut by the echo of a command), the status is asked for again
static char outcome[112];
#define OUTCOME(level, ...)                                         \
	do {                                                        \
		snprintk(outcome, sizeof(outcome), __VA_ARGS__);    \
		LOG_##level("ota: %s", outcome);                    \
	} while (0)

static void stall_fn(struct k_work *work)
{
	int s = atomic_get(&state);
	if (s == OTA_SENDING && atomic_cas(&state, OTA_SENDING, OTA_IDLE))
		OUTCOME(WRN, "tracker %u stopped asking at %u of %u bytes", target, asked, img_size);
	else if (s == OTA_OFFERING && atomic_cas(&state, OTA_OFFERING, OTA_IDLE))
		OUTCOME(WRN, "tracker %u did not answer the offer (off, not paired, or firmware without OTA protocol %u)",
			target, OTA_PROTOCOL);
}
static K_WORK_DELAYABLE_DEFINE(stall_work, stall_fn);

bool ota_busy(void)
{
	return atomic_get(&state) != OTA_IDLE;
}

/* ---- radio (ESB event handler, interrupt context) ---- */

void ota_esb_tracker_frame(void)
{
	if (atomic_get(&state) != OTA_OFFERING)
		return;
	// Rides on the ACK of the next frame on pipe 1, from whichever tracker sends next; one is
	// queued per frame, as each ACK uses up the payload of the one before.
	struct esb_payload p = {.pipe = 1, .length = OTA_OFFER_LEN};
	p.data[0] = OTA_MSG_OFFER;
	p.data[1] = target;
	p.data[2] = OTA_PROTOCOL;
	p.data[3] = session;
	ota_put_u32(&p.data[4], img_size);
	ota_put_u32(&p.data[8], img_crc);
	ota_put_u32(&p.data[12], img_board);
	esb_write_payload(&p);
}

void ota_esb_rx(const struct esb_payload *payload)
{
	const uint8_t *d = payload->data;
	int s = atomic_get(&state);
	if (payload->length == OTA_REQ_LEN && d[0] == OTA_MSG_REQ) {
		if ((s != OTA_OFFERING && s != OTA_SENDING) || d[1] != target)
			return;
		uint32_t position = ota_get_u24(&d[2]);
		if (position >> OTA_OFFSET_BITS != session)
			return; // left over from an earlier update
		uint32_t offset = position & OTA_OFFSET_MASK;
		if (s == OTA_OFFERING) {
			atomic_set(&state, OTA_SENDING);
			start_time = k_uptime_get();
			next_log = img_size / 10;
			LOG_INF("ota: tracker %u accepted, sending %u bytes", target, img_size);
		}
		k_work_reschedule(&stall_work, K_MSEC(STALL_TIMEOUT_MS));
		if (offset >= img_size)
			return;
		asked = offset;
		if (offset >= next_log) {
			LOG_INF("ota: tracker %u at %u%%", target, (uint32_t)((uint64_t)offset * 100 / img_size));
			next_log += img_size / 10;
		}
		// Queue exactly the chunk asked for. It rides on the ACK of the tracker's next frame (the
		// ACK of this one is already out), and the tracker asks again at once whenever an ACK did
		// not bring its chunk: two frames per chunk, and nothing to get out of step.
		uint32_t n = MIN(OTA_CHUNK_MAX, img_size - offset);
		if (offset + n > received)
			return; // the PC has not sent it yet: the tracker asks again
		compiler_barrier(); // the window holds everything below received (ota_hid_data)
		struct esb_payload p = {.pipe = OTA_PIPE, .length = OTA_CHUNK_HEADER + n};
		p.data[0] = OTA_MSG_CHUNK;
		ota_put_u24(&p.data[1], position);
		for (uint32_t i = 0; i < n; i++)
			p.data[OTA_CHUNK_HEADER + i] = window[(offset + i) % WINDOW];
		esb_write_payload(&p);
		return;
	}
	if (payload->length == OTA_DONE_LEN && d[0] == OTA_MSG_DONE && d[1] == target &&
	    (s == OTA_OFFERING || s == OTA_SENDING)) {
		atomic_set(&state, OTA_IDLE);
		k_work_cancel_delayable(&stall_work);
		if (d[2] == OTA_STATUS_INSTALLED)
			OUTCOME(INF, "tracker %u received the image in %u s and reboots into it", target,
				(uint32_t)((k_uptime_get() - start_time) / 1000));
		else if (s == OTA_OFFERING)
			OUTCOME(WRN, "tracker %u refused the update: %s (its OTA protocol %u, this receiver's %u)",
				target, ota_status_name(d[2]), d[3], OTA_PROTOCOL);
		else
			OUTCOME(WRN, "tracker %u failed: %s, it keeps its firmware", target, ota_status_name(d[2]));
	}
}

/* ---- image data from the PC (HID OUT reports) ---- */

void ota_hid_data(const uint8_t *report, int len)
{
	int s = atomic_get(&state);
	if ((s != OTA_OFFERING && s != OTA_SENDING) || len < OTA_HID_HEADER)
		return;
	uint32_t offset = ota_get_u24(&report[1]);
	uint32_t n = MIN(report[4], len - OTA_HID_HEADER);
	// Only the next part, only inside the window, never past the end: anything else is dropped,
	// and the PC goes on from what the status says
	if (n == 0 || offset != received || offset + n > img_size || offset + n > asked + WINDOW)
		return;
	for (uint32_t i = 0; i < n; i++)
		window[(offset + i) % WINDOW] = report[OTA_HID_HEADER + i];
	compiler_barrier(); // the data is in the window before the radio interrupt sees it counted
	received = offset + n;
}

/* ---- console ---- */

static void print_status(void)
{
	int s = atomic_get(&state);
	printk("ota: %s", state_names[s]);
	if (s != OTA_IDLE)
		printk(", tracker %u, %u bytes, received %u, asked %u", target, img_size, received, asked);
	else if (outcome[0])
		printk(", last: %s", outcome);
	printk("\n");
}

void ota_console(int argc, char **argv)
{
	const char *cmd = argc > 1 ? argv[1] : "status";
	if (strcmp(cmd, "begin") == 0 && argc == 6) {
		// ota begin <size> <crc32 hex> <board crc32 hex> <tracker id>: offer at once, data follows
		remote_config_cancel(); // the offer takes the ACKs on pipe 1
		atomic_set(&state, OTA_IDLE);
		k_work_cancel_delayable(&stall_work);
		img_size = strtoul(argv[2], NULL, 0);
		img_crc = strtoul(argv[3], NULL, 16);
		img_board = strtoul(argv[4], NULL, 16);
		target = strtoul(argv[5], NULL, 0);
		received = 0;
		asked = 0;
		if (img_size == 0 || img_size > OTA_OFFSET_MASK) {
			printk("ota: error: size %u\n", img_size);
			return;
		}
		session = session % OTA_SESSIONS + 1;
		outcome[0] = '\0';
		atomic_set(&state, OTA_OFFERING);
		k_work_reschedule(&stall_work, K_MSEC(STALL_TIMEOUT_MS)); // no answer to the offer
		printk("ota: begin %u, offering to tracker %u, protocol %u\n", img_size, target, OTA_PROTOCOL);
	} else if (strcmp(cmd, "stop") == 0) {
		if (atomic_set(&state, OTA_IDLE) != OTA_IDLE)
			snprintk(outcome, sizeof(outcome), "stopped from the console");
		k_work_cancel_delayable(&stall_work);
		print_status();
	} else if (strcmp(cmd, "status") == 0) {
		print_status();
	} else {
		printk("Usage: ota begin <size> <crc32 hex> <board crc32 hex> <tracker id> | ota stop | ota status\n"
		       "       (tools/ota.py does all of it; the image comes as HID OUT reports)\n");
	}
}
```

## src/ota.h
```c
#ifndef SLIMENRF_OTA
#define SLIMENRF_OTA

#include <esb.h>

// Tracker firmware updates over the radio, the receiver's part (docs/OTA.md, ota_proto.h):
// the PC streams the image through this receiver's console ("ota" commands, tools/ota.py) into a
// RAM window, while the tracker fetches it over the radio.

// The "ota" console command (argv[0] is "ota"): begin, stop, status. The PC polls the status to
// keep within the window.
void ota_console(int argc, char **argv);

// Image data from the PC: a HID OUT report [OTA_HID_DATA][offset u24][length][data], 64 bytes.
// Only the next offset is taken, and only within the window; the PC sees from the status where
// to go on.
#define OTA_HID_DATA 0xF5
#define OTA_HID_HEADER 5
void ota_hid_data(const uint8_t *report, int len);

// ESB event handler, interrupt context: a frame on the OTA pipe (requests and results from the
// tracker being updated), and every tracker frame on pipe 1 (keeps an update offer queued).
void ota_esb_rx(const struct esb_payload *payload);
void ota_esb_tracker_frame(void);

// Offering or sending an update: no settings requests meanwhile (remote_config.c)
bool ota_busy(void);

#endif
```

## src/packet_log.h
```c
/*
	SlimeVR Code is placed under the MIT license
	Copyright (c) 2026 SlimeVR Contributors

	Permission is hereby granted, free of charge, to any person obtaining a copy
	of this software and associated documentation files (the "Software"), to deal
	in the Software without restriction, including without limitation the rights
	to use, copy, modify, merge, publish, distribute, sublicense, and/or sell
	copies of the Software, and to permit persons to whom the Software is
	furnished to do so, subject to the following conditions:

	The above copyright notice and this permission notice shall be included in
	all copies or substantial portions of the Software.

	THE SOFTWARE IS PROVIDED "AS IS", WITHOUT WARRANTY OF ANY KIND, EXPRESS OR
	IMPLIED, INCLUDING BUT NOT LIMITED TO THE WARRANTIES OF MERCHANTABILITY,
	FITNESS FOR A PARTICULAR PURPOSE AND NONINFRINGEMENT. IN NO EVENT SHALL THE
	AUTHORS OR COPYRIGHT HOLDERS BE LIABLE FOR ANY CLAIM, DAMAGES OR OTHER
	LIABILITY, WHETHER IN AN ACTION OF CONTRACT, TORT OR OTHERWISE, ARISING FROM,
	OUT OF OR IN CONNECTION WITH THE SOFTWARE OR THE USE OR OTHER DEALINGS IN
	THE SOFTWARE.
*/
#ifndef SLIMENRF_PACKET_LOG
#define SLIMENRF_PACKET_LOG

#include <stdbool.h>
#include <stdint.h>

// Why the ESB handler threw a tracker packet away. The tracker still got its radio ACK
// for all of these, so from the tracker's side the link looks fine.
enum packet_drop {
	PACKET_DROP_UNKNOWN_ID, // id not stored on this receiver: paired elsewhere, or removed here
	PACKET_DROP_CHECKSUM,
	PACKET_DROP_SEQUENCE,
	PACKET_DROP_DUPLICATE, // repeat of the last frame: the tracker missed the ACK and sent it again
	PACKET_DROP_COUNT
};

// Records one tracker packet; a low priority thread logs drops and silent trackers, and with
// CONFIG_PACKET_LOG_ORIENTATION each tracker's orientation and packet rate every interval.
// Never blocks; safe from the ESB event handler. No-op when the log is disabled.
//
// Link diagnostics ("diag on" on the console, off at boot): packet_log_frame() sees every 21-byte
// ESB data frame before the receiver's own filters. Per tracker and interval it logs frames
// received, sequence numbers that never arrived (lost in the air), repeats (the tracker missed the
// ACK), the longest silence and RSSI, plus a timeline of 50 ms slots; also the radio's CRC
// good/bad counts for all trackers together, and each silence that lost frames.
#if CONFIG_PACKET_LOG
void packet_log_put(const uint8_t *packet, uint8_t rssi);
void packet_log_drop(uint8_t id, enum packet_drop reason);
void packet_log_frame(const uint8_t *frame, uint8_t rssi);
void packet_log_set_diag(bool on);
bool packet_log_diag(void);
#else
static inline void packet_log_put(const uint8_t *packet, uint8_t rssi) { (void)packet; (void)rssi; }
static inline void packet_log_drop(uint8_t id, enum packet_drop reason) { (void)id; (void)reason; }
static inline void packet_log_frame(const uint8_t *frame, uint8_t rssi) { (void)frame; (void)rssi; }
static inline void packet_log_set_diag(bool on) { (void)on; }
static inline bool packet_log_diag(void) { return false; }
#endif

#endif
```

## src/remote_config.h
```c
#ifndef SLIMENRF_REMOTE_CONFIG
#define SLIMENRF_REMOTE_CONFIG

#include <stdbool.h>
#include <esb.h>

// Tracker settings over the radio, the receiver's part (ota_proto.h CFG_MSG_*, docs/OTA.md): the
// PC asks on the console ("cfg", tools/remote_config.py), the request rides on the ACKs of tracker
// frames until the tracker answers on the OTA pipe.

// The "cfg" console command (argv[0] is "cfg"): <tracker id> get|set|reset <setting id> [value],
// status.
void remote_config_console(int argc, char **argv);

// ESB event handler, interrupt context: an answer on the OTA pipe, and every tracker frame on
// pipe 1 (keeps the request queued while waiting).
void remote_config_esb_rx(const struct esb_payload *payload);
void remote_config_esb_tracker_frame(void);
// BLE mode (connection/ble.c): a notification from a tracker's settings characteristic
void remote_config_ble_rx(const uint8_t *data, uint16_t length);

// Waiting for an answer: no firmware update offer meanwhile, they share the ACKs on pipe 1
bool remote_config_busy(void);
// A firmware update starts: give up the request
void remote_config_cancel(void);

#endif
```
